# pse84_a0 register map
Vendor: Infineon Technologies; Series: PSE84_A0; File version: 1.0
CPU: CM33 r0p1, little endian, MPU, FPU, VTOR, 3 interrupt priority bits
Registers are 32-bit, read-write, reset 0x0 unless marked. A register's access mark holds for its fields unless they carry their own. Offsets are from the block's base; [hi:lo] are bit positions; {n}, {i} and the like mark numbered series.

## MXCM55 — MXCM55-0/1
Base 0x44160000
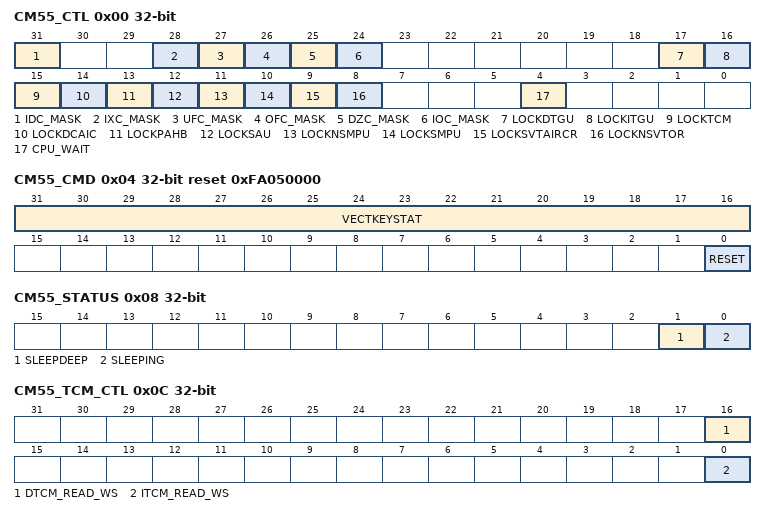
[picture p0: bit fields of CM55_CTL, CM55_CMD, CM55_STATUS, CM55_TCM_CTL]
0x00 CM55_CTL — Control
  [31] IDC_MASK
  [28] IXC_MASK
  [27] UFC_MASK
  [26] OFC_MASK
  [25] DZC_MASK
  [24] IOC_MASK — CPU floating point unit (FPU) exception mask for the CPU's FPCSR.IOC 'invalid operation' exception condition: '0': The CPU's exception condition does NOT activate the CPU's floating point interrupt. '1': the CPU's exception condition activates the CPU's floating point interrupt. Note: the ARM architecture does NOT support FPU exceptions; i.e. there is no precise FPU exception handler. Instead, FPU conditions are captured in the CPU's FPCSR register and the conditions are provided as CPU interface signals. The interface signals are 'masked' with the fields provided by this register (CM55_CTL). The 'masked' signals are reduced/OR-ed into a single CPU floating point interrupt signal. The associated CPU interrupt handler allows for imprecise handling of FPU exception conditions. Note: the CPU's FPCSR exception conditions are 'sticky'. Typically, the CPU FPU interrupt handler will clear the exception condition(s) to '0'. Note: by default, the FPU exception masks are '0'. Therefore, FPU exception conditions will NOT activate the CPU's floating point interrupt.
  [17] LOCKDTGU — Asserting this bit prevents changes to the security gating configuration of the DTCM. '1': Disables writes to the DTGUCTRL, DTGU_LUTn from software or from a debug agent connected to the processor. '0': Unlocks these registers.
  [16] LOCKITGU — Asserting this bit prevents changes to the security gating configuration of the ITCM. '1': Disables writes to the ITGUCTRL, ITGU_LUTn from software or from a debug agent connected to the processor. '0': Unlocks these registers.
  [15] LOCKTCM — Asserting this bit prevents changes to the TCM configuration. All writes to the registers are ignored. '1': Disables writes to the ITCMCR, DTCMCR from software or from a debug agent connected to the processor. '0': Unlocks these registers.
  [14] LOCKDCAIC
  [13] LOCKPAHB
  [12] LOCKSAU
  [11] LOCKNSMPU
  [10] LOCKSMPU
  [9] LOCKSVTAIRCR
  [8] LOCKNSVTOR
  [4] CPU_WAIT
0x04 CM55_CMD reset 0xFA050000 — Command
  [31:16] VECTKEYSTAT ro — Register key (to prevent accidental writes). - Should be written with a 0x05fa key value for the write to take effect. - Always reads as 0xfa05.
  [0] RESET — CM55 Processor reset: '1': RESET. Processor reset is activated. After SW set this field to '1', HW automatically clears this field to '0'. This effectively results in a CM55 reset, followed by a CM55 warm boot. This bit effectively enables WARM_RST state of the CM55 PPU and works only when dynamic transitions are enabled in CM55 PPU. '0': No reset of CM55. Note: The intent is that this bit is modified only through an external probe or by the other CPU while this CM55 is in Sleep or DeepSleep. If this field is set to '1' by this CM55 itself, it should be done under controlled conditions (such that undesirable side effects can be prevented). Note: The CM55 CPU has a AIRCR.SYSRESETREQ register field that allows the CM55 to reset the complete device (RESET field in this register only resets the CM55), resulting in a warm boot. This CPU register field has similar 'built-in protection' as this register to prevent accidental system writes (the upper 16-bits of the register need to be written with a 0x05fa key value; see CPU user manual for more details).
0x08 CM55_STATUS ro — Status
  [1] SLEEPDEEP — Specifies if the CPU is in Sleep or DeepSleep power mode. See SLEEPING field.
  [0] SLEEPING — Specifies if the CPU is in Active, Sleep or DeepSleep power mode: - Active power mode: SLEEPING is '0'. - Sleep power mode: SLEEPING is '1' and SLEEPDEEP is '0'. - DeepSleep power mode: SLEEPING is '1' and SLEEPDEEP is '1'.
0x0C CM55_TCM_CTL — TCM control
  [16] DTCM_READ_WS — DTCM read wait states (writes have no wait states). '0': 0 wait states. '1': 1 wait state.
  [0] ITCM_READ_WS — ITCM read wait states (writes have no wait states). '0': 0 wait states. '1': 1 wait state.
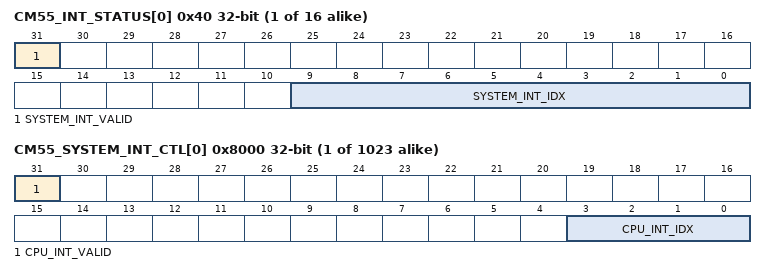
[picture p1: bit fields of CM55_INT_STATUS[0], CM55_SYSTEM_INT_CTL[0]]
{0x40+4i} CM55_INT_STATUS[{i}] (i=0..15) ro (reset mask 0x80000000) — CM55 interrupt status
  [31] SYSTEM_INT_VALID — Valid indication for SYSTEM_INT_IDX. When '0', no system interrupt for CPU interrupt 0 is valid/activated.
  [9:0] SYSTEM_INT_IDX — Lowest CM55 activated system interrupt index for given CPU interrupt. Multiple system interrupts can be mapped on the same CPU interrupt. The selected system interrupt is the system interrupt with the lowest system interrupt index that has an activated interrupt request at the time of the fetch (system_interrupts[SYSTEM_INT_IDX] is '1'). The CPU interrupt handler SW can read SYSTEM_INT_IDX to determine the system interrupt that activated the handler.
{0x80+4i} CM55_NMI_CTL[{i}] (i=0..3) reset 0x3FF — CM55 NMI control
  [9:0] SYSTEM_INT_IDX — System interrupt select for CPU NMI. The reset value ('1023') ensures that the CPU NMI is NOT connected to any system interrupt after DeepSleep reset.
0xC0 CM55_EVENT_CTL — CM55 EVENT control
  [4:0] MASK
0x1000 CM55_S_VECTOR_TABLE_BASE — CM55 secure vector table base
  [31:7] ADDR25 — Address of CM55 secure vector table to be used at reset. Default value: ADDR25: 0x0200000 (points to Secure TCM start address i.e. 0x1000_0000).
0x1004 CM55_NS_VECTOR_TABLE_BASE — CM55 non-secure vector table base
  [31:7] ADDR25 — Address of CM55 non-secure vector table to be used at reset. Default value: ADDR25: 0x0000000 (points to Non-Secure TCM start address i.e. 0x0000_0000).
0x20C0 WOUNDING
  [0] FPU_WOUND — When set to '1', disables support for CM55 FPU.
{0x8000+4i} CM55_SYSTEM_INT_CTL[{i}] (i=0..1022) (reset mask 0x80000000) — CM55 system interrupt control
  [31] CPU_INT_VALID — Interrupt enable: '0': Disabled. The system interrupt will NOT be mapped to any CPU interrupt. '1': Enabled. The system interrupt is mapped on CPU interrupt CPU_INT_IDX. Note: the CPUs have dedicated XXX_SYSTEM_INT_CTL registers. In other words, the CPUs can use different CPU interrupts for the same system interrupt. However, typically only one of the CPUs will have the ENABLED field of a specific system interrupt set to '1'.
  [3:0] CPU_INT_IDX — CPU interrupt index (legal range [0, 7]). This field specifies to which CPU interrupt the system interrupt is mapped. E.g., if CPU_INT_IDX is '6', the system interrupt is mapped to CPU interrupt '6'. Note: it is possible to map multiple system interrupts to the same CPU interrupt. It is advised to assign different priorities to the CPU interrupts and to assign system interrupts to CPU interrupts accordingly.
